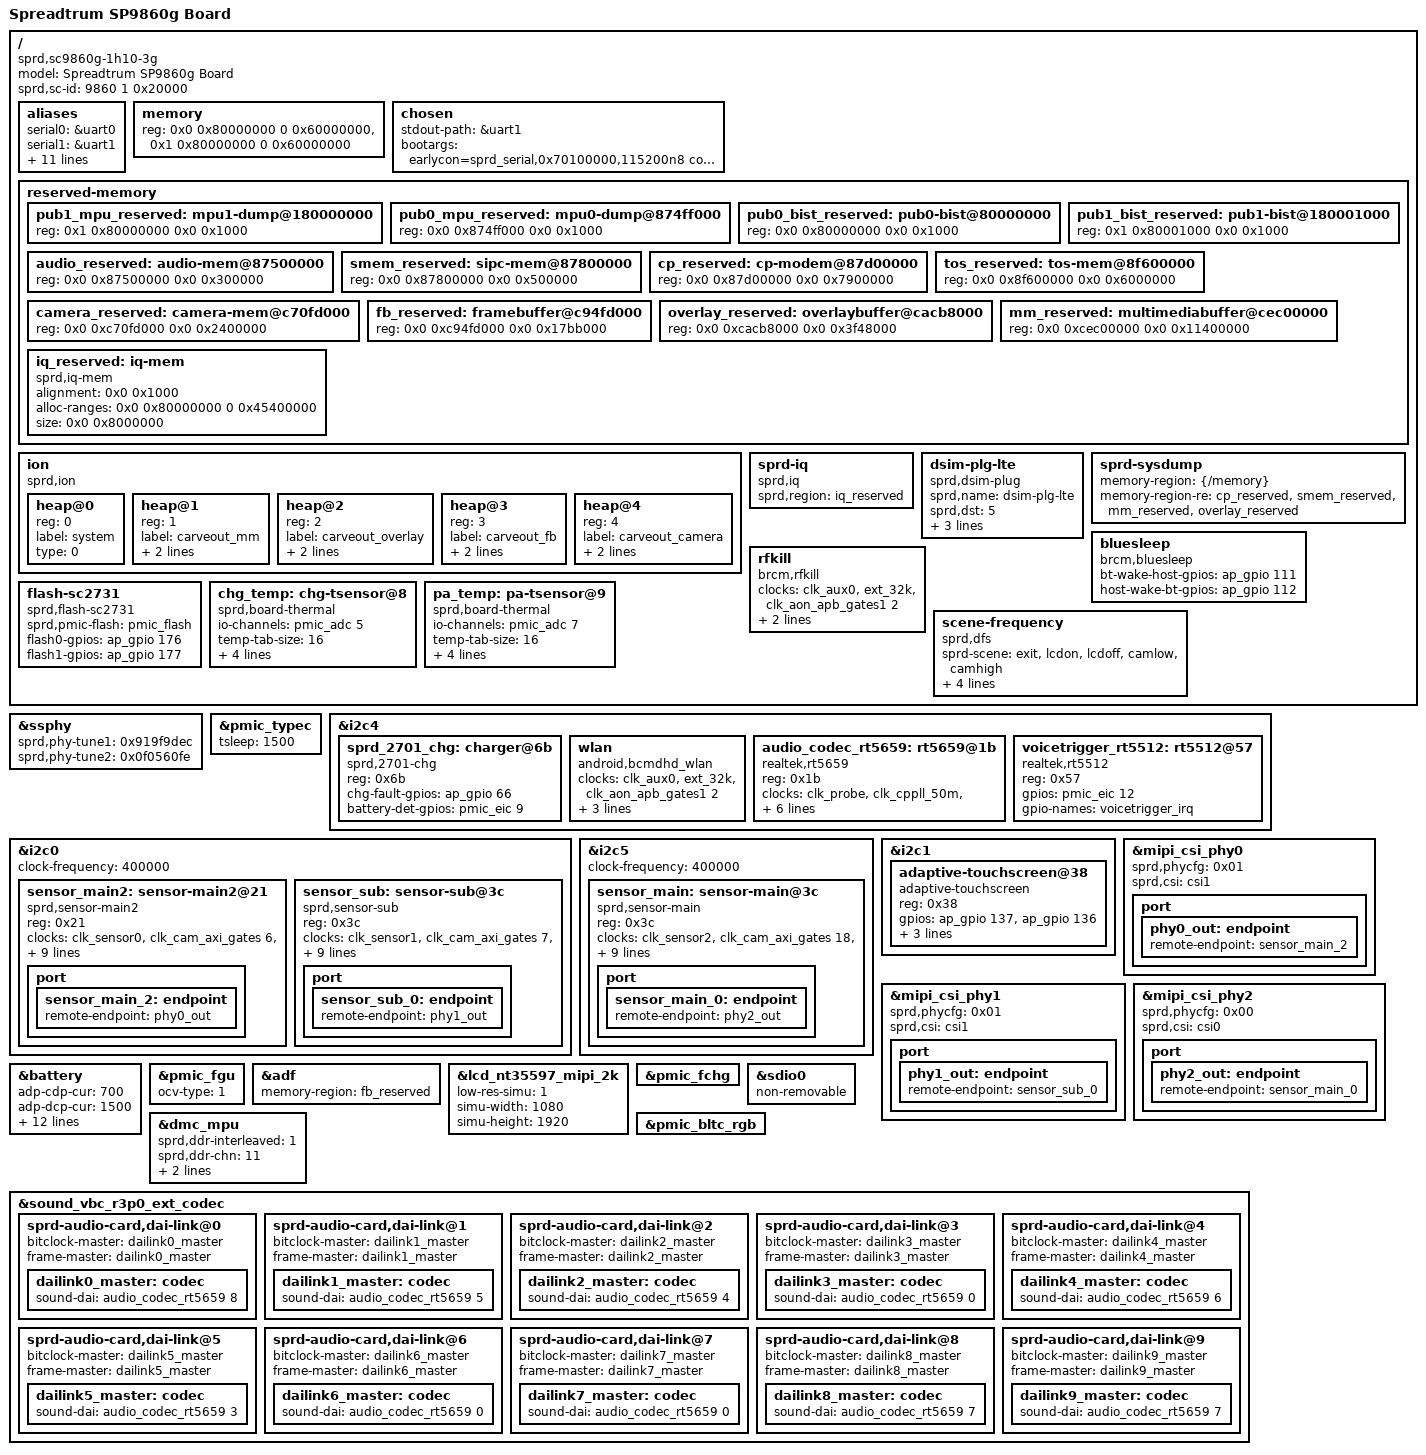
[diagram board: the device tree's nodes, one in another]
/*
 * Spreadtrum SP9860g board DTS file
 *
 * Copyright (C) 2016, Spreadtrum Communications Inc.
 *
 * This file is licensed under a dual GPLv2 or X11 license.
 */

/dts-v1/;

#include "sc9860g.dtsi"
#include "sc2731.dtsi"
#include "sprd-battery.dtsi"
#include "sp98x0-common.dtsi"
#include "sprd-sound.dtsi"

/ {
	model = "Spreadtrum SP9860g Board";

	compatible = "sprd,sc9860g-1h10-3g";

	sprd,sc-id = <9860 1 0x20000>;

	aliases {
		serial0 = &uart0;
		serial1 = &uart1;
		serial2 = &uart2;
		serial3 = &uart3;
		i2c0 = &i2c0;
		i2c1 = &i2c1;
		i2c4 = &i2c4;
		i2c5 = &i2c5;
		hwspinlock1 = &hwslock1;
		dmc_mpu = &dmc_mpu;
		thm-sensor7 = &pmic_thermal;
		thm-sensor8 = &chg_temp;
		thm-sensor9 = &pa_temp;
	};

	memory{
		device_type = "memory";
		reg = <0x0 0x80000000 0 0x60000000>, <0x1 0x80000000 0 0x60000000>;
	};

	chosen {
		stdout-path = &uart1;
		bootargs = "earlycon=sprd_serial,0x70100000,115200n8 console=ttyS1,115200n8 loglevel=1 androidboot.hardware=sp9860g_1h10_3g memblock=debug bootmem_debug=1";
	};

	reserved-memory {
		#address-cells = <2>;
		#size-cells = <2>;
		ranges;

		pub1_mpu_reserved: mpu1-dump@180000000 {
			reg = <0x1 0x80000000 0x0 0x1000>;
		};

		pub0_mpu_reserved: mpu0-dump@874ff000 {
			reg = <0x0 0x874ff000 0x0 0x1000>;
		};

		pub0_bist_reserved: pub0-bist@80000000 {
			reg = <0x0 0x80000000 0x0 0x1000>;
		};

		pub1_bist_reserved: pub1-bist@180001000 {
			reg = <0x1 0x80001000 0x0 0x1000>;
		};

		audio_reserved: audio-mem@87500000 {
			reg = <0x0 0x87500000 0x0 0x300000>;
		};

		smem_reserved: sipc-mem@87800000 {
			reg = <0x0 0x87800000 0x0 0x500000>;
		};

		cp_reserved: cp-modem@87d00000 {
			reg = <0x0 0x87d00000 0x0 0x7900000>;
		};

		tos_reserved: tos-mem@8f600000 {
			reg = <0x0 0x8f600000 0x0 0x6000000>;
		};

		camera_reserved: camera-mem@c70fd000{
			reg = <0x0 0xc70fd000 0x0 0x2400000>;
		};

		fb_reserved: framebuffer@c94fd000{
			reg = <0x0 0xc94fd000 0x0 0x17bb000>;
		};

		overlay_reserved: overlaybuffer@cacb8000{
			reg = <0x0 0xcacb8000 0x0 0x3f48000>;
		};

		mm_reserved: multimediabuffer@cec00000{
			reg = <0x0 0xcec00000 0x0 0x11400000>;
		};

		iq_reserved: iq-mem{
			compatible = "sprd,iq-mem";
			alignment = <0x0 0x1000>;
			alloc-ranges = <0x0 0x80000000 0 0x45400000>;
			size = <0x0 0x8000000>;
		};
	};

	ion {
		compatible = "sprd,ion";
		#address-cells = <1>;
		#size-cells = <0>;

		heap@0 {
			reg = <0>;
			label = "system";
			type = <0>;
		};

		heap@1 {
			reg = <1>;
			label = "carveout_mm";
			type = <2>;
			memory-region = <&mm_reserved>;
		};

		heap@2 {
			reg = <2>;
			label = "carveout_overlay";
			type = <2>;
			memory-region = <&overlay_reserved>;
		};

		heap@3 {
			reg = <3>;
			label = "carveout_fb";
			type = <2>;
			memory-region = <&fb_reserved>;
		};

		heap@4 {
			reg = <4>;
			label = "carveout_camera";
			type = <2>;
			memory-region = <&camera_reserved>;
		};
	};

	sprd-iq {
		compatible = "sprd,iq";
		sprd,region = <&iq_reserved>;
	};

	dsim-plg-lte {
		compatible = "sprd,dsim-plug";
		sprd,name = "dsim-plg-lte";
		sprd,dst = <5>;
		sprd,channel = <23>;
		sim1-gpios = <&ap_gpio 40 0>;
		sim2-gpios = <&ap_gpio 41 0>;
	};

	sprd-sysdump {
		memory-region = <&{/memory}>;
		memory-region-re = <&cp_reserved>,<&smem_reserved>,
				<&mm_reserved>,<&overlay_reserved>;
	};

	bluesleep {
		compatible = "brcm,bluesleep";
		bt-wake-host-gpios = <&ap_gpio 111 0>;
		host-wake-bt-gpios = <&ap_gpio 112 0>;
	};

	rfkill {
		compatible = "brcm,rfkill";
		clock-names = "clk_32k","source","enable";
		clocks = <&clk_aux0>,<&ext_32k>,
			 <&clk_aon_apb_gates1 2>;
		power-gpios = <&ap_gpio 113 0>;
		reset-gpios = <&ap_gpio 122 0>;
	};

	flash-sc2731 {
		compatible = "sprd,flash-sc2731";
		sprd,pmic-flash = <&pmic_flash>;
		flash0-gpios = <&ap_gpio 176 0>;
		flash1-gpios = <&ap_gpio 177 0>;
	};

	chg_temp:chg-tsensor@8 {
		compatible = "sprd,board-thermal";
		#thermal-sensor-cells = <1>;
		io-channels = <&pmic_adc 5>;
		io-channel-names = "adc_temp";
		temp-tab-size = <16>;
		temp-tab-val = <1140 1132 1109 1074 983 838 654 413
				316 238 178 133 99 75 57 43>;
		temp-tab-temp = <558 596 704 806 953 1101 1248 1450
				1549 1649 1749 1849 1951 2049 2148 2252>;
	};

	pa_temp:pa-tsensor@9 {
		compatible = "sprd,board-thermal";
		#thermal-sensor-cells = <1>;
		io-channels = <&pmic_adc 7>;
		io-channel-names = "adc_temp";
		temp-tab-size = <16>;
		temp-tab-val = <1140 1132 1109 1074 983 838 654 413
				316 238 178 133 99 75 57 43>;
		temp-tab-temp = <558 596 704 806 953 1101 1248 1450
				1549 1649 1749 1849 1951 2049 2148 2252>;
	};

	scene-frequency {
		compatible = "sprd,dfs";
		sprd-scene = "exit", "lcdon", "lcdoff", "camlow", "camhigh";
		sprd-freq = <400 400 400 600 1200>;
		overflow = <4915200 12160000 17040000 98304000>;
		underflow = <0 3276800 11200000 16800000>;
		timer = <10>;
	};
};

&ssphy {
	sprd,phy-tune1 = <0x919f9dec>;
	sprd,phy-tune2 = <0x0f0560fe>;
};

&pmic_typec {
	tsleep = <1500>;
};

&i2c4 {
	status = "okay";
	sprd_2701_chg: charger@6b {
		compatible = "sprd,2701-chg";
		reg = <0x6b>;
		chg-fault-gpios = <&ap_gpio 66 0>;
		battery-det-gpios = <&pmic_eic 9 0>;
	};

	wlan {
		compatible = "android,bcmdhd_wlan";
		clock-names = "clk_32k","source","enable";
		clocks = <&clk_aux0>,<&ext_32k>,
			 <&clk_aon_apb_gates1 2>;
		wl-reg-on-gpios = <&ap_gpio 83 0>;
		wl-host-wake-gpios = <&ap_gpio 84 0>;
		sdhci-name = <&sdio1>;
	};

	audio_codec_rt5659: rt5659@1b {
		compatible = "realtek,rt5659";
		#sound-dai-cells = <1>;
		reg = <0x1b>;
		clock-names = "mclk", "source", "enable";
		clocks = <&clk_probe>, <&clk_cppll_50m>,
			 <&clk_aon_apb_gates1 5>;
		ldo-gpios = <&ap_gpio 181 0>;
		reset-gpios = <&ap_gpio 34 0>;
		realtek,gpio-jd2-sel = <7>; /* 0 ~ 7 <-> GPIO9 ~ GPIO15 */
		/* 0: uses 2 pins to detect hp; 1: uses 1 pin. */
		realtek,hp-det-one-pin = <1>;
		realtek,fixed-rate = <48000>; /* fixed sample rate. unit: Hz */
	};

	voicetrigger_rt5512: rt5512@57 {
		compatible = "realtek,rt5512";
		reg = <0x57>;
		gpios = <&pmic_eic 12 0> ;
		gpio-names = "voicetrigger_irq";
	};
};

&i2c0 {
	status = "okay";
	clock-frequency = <400000>;

	sensor_main2: sensor-main2@21 {
		compatible = "sprd,sensor-main2";
		reg = <0x21>;
		clock-names = "clk_src","sensor_eb",
			"clk_96m","clk_76m8",
			"clk_48m","clk_26m";
		clocks  = <&clk_sensor0>,<&clk_cam_axi_gates 6>,
			<&clk_twpll_96m>,<&clk_twpll_76m8>,
			<&clk_twpll_48m>,<&ext_26m>;
		vddio-supply = <&vddcamio>;
		vddcamd-supply = <&vddcamd1>;
		vddcama-supply = <&vddcama1>;
		vddcammot-supply = <&vddcammot>;
		reset-gpios = <&ap_gpio 123 0>;
		power-down-gpios = <&ap_gpio 124 0>;
		host = "dcam1";
		port {
			sensor_main_2: endpoint {
				remote-endpoint = <&phy0_out>;
			};
		};
	};

	sensor_sub: sensor-sub@3c {
		compatible = "sprd,sensor-sub";
		reg = <0x3c>;
		clock-names = "clk_src","sensor_eb",
			"clk_96m","clk_76m8",
			"clk_48m","clk_26m";
		clocks = <&clk_sensor1>,<&clk_cam_axi_gates 7>,
			<&clk_twpll_96m>,<&clk_twpll_76m8>,
			<&clk_twpll_48m>,<&ext_26m>;
		vddio-supply = <&vddcamio>;
		vddcama-supply = <&vddcama1>;
		vddcamd-supply = <&vddcamd1>;
		vddcammot-supply = <&vddcammot>;
		reset-gpios = <&ap_gpio 157 0>;
		power-down-gpios = <&ap_gpio 125 0>;
		host = "dcam1";
		port {
			sensor_sub_0: endpoint {
				remote-endpoint = <&phy1_out>;
			};
		};
	};

};

&i2c5 {
	status = "okay";
	clock-frequency = <400000>;

	sensor_main: sensor-main@3c {
		compatible = "sprd,sensor-main";
		reg = <0x3c>;
		clock-names = "clk_src","sensor_eb",
			"clk_96m","clk_76m8",
			"clk_48m","clk_26m";
		clocks = <&clk_sensor2>,<&clk_cam_axi_gates 18>,
			<&clk_twpll_96m>,<&clk_twpll_76m8>,
			<&clk_twpll_48m>,<&ext_26m>;
		vddio-supply = <&vddcamio>;
		vddcama-supply = <&vddcama0>;
		vddcamd-supply = <&vddcamd0>;
		vddcammot-supply = <&vddcammot>;
		reset-gpios = <&ap_gpio 168 0>;
		power-down-gpios = <&ap_gpio 169 0>;
		host = "dcam0";
		port {
			sensor_main_0: endpoint {
				remote-endpoint = <&phy2_out>;
			};
		};
	};

};

&i2c1 {
	status = "okay";

	adaptive-touchscreen@38 {
		compatible = "adaptive-touchscreen";
		reg = <0x38>;
		gpios = <&ap_gpio 137 0
			&ap_gpio 136 0>;
		controller = "focaltech,FT5x46";
		surface-width = <1080>;
		surface-height = <1920>;
	};
};

&mipi_csi_phy0 {
	status = "okay";

	sprd,phycfg = <0x01>;
	sprd,csi = <&csi1>;
	port {
		phy0_out: endpoint {
			remote-endpoint = <&sensor_main_2>;
		};
	};
};

&mipi_csi_phy1 {
	status = "okay";

	sprd,phycfg = <0x01>;
	sprd,csi = <&csi1>;
	port {
		phy1_out: endpoint {
			remote-endpoint = <&sensor_sub_0>;
		};
	};
};

&mipi_csi_phy2 {
	status = "okay";

	sprd,phycfg = <0x00>;
	sprd,csi = <&csi0>;
	port {
		phy2_out: endpoint {
			remote-endpoint = <&sensor_main_0>;
		};
	};
};

&battery {
	adp-cdp-cur = <700>;
	adp-dcp-cur = <1500>;
	adp-sdp-cur = <450>;
	chg-end-vol = <4350>;
	chg-end-vol-check = <4330>;
	chg-bat-safety-vol = <4430>;
	rechg-vol = <4270>;
	rsense-real = <100>;
	rint = <320>;
	cnom = <2780>;
	ocv-tab-vol = <4360 4249 4189 4133 4081 4034 3991
			3953 3910 3866 3836 3813 3795 3782
			3774 3765 3750 3726 3687 3658 3400>;
	ocv-tab-cap = <100  95   90   85   80   75   70
			65   60   55   50   45   40   35
			30   25   20   15   10   5    0>;
};

&pmic_fgu {
	ocv-type = <1>;
};

&adf {
	memory-region = <&fb_reserved>;
};

&lcd_nt35597_mipi_2k {
	low-res-simu = <1>;
	simu-width = <1080>;
	simu-height = <1920>;
};

&pmic_fchg {
	status = "okay";
};

&sdio0 {
	non-removable;
};

&dmc_mpu {
	sprd,ddr-interleaved = <1>;
	sprd,ddr-chn = <11>;
	memory-region = <&pub0_mpu_reserved>,<&pub1_mpu_reserved>;
};

&pmic_bltc_rgb {
	status = "okay";
};

&sound_vbc_r3p0_ext_codec {
	status = "okay";
	sprd-audio-card,dai-link@0 {
		bitclock-master = <&dailink0_master>;
		frame-master = <&dailink0_master>;
		dailink0_master: codec {
			/* rt5659-aif1 */
			sound-dai = <&audio_codec_rt5659 8>;
		};
	};
	sprd-audio-card,dai-link@1 {
		bitclock-master = <&dailink1_master>;
		frame-master = <&dailink1_master>;
		dailink1_master: codec {
			/* rt5659-aif1-voice */
			sound-dai = <&audio_codec_rt5659 5>;
		};
	};
	sprd-audio-card,dai-link@2 {
		bitclock-master = <&dailink2_master>;
		frame-master = <&dailink2_master>;
		dailink2_master: codec {
			/* rt5659-aif1-fast */
			sound-dai = <&audio_codec_rt5659 4>;
		};
	};
	sprd-audio-card,dai-link@3 {
		bitclock-master = <&dailink3_master>;
		frame-master = <&dailink3_master>;
		dailink3_master: codec {
			/* rt5659-aif1 */
			sound-dai = <&audio_codec_rt5659 0>;
		};
	};
	sprd-audio-card,dai-link@4 {
		bitclock-master = <&dailink4_master>;
		frame-master = <&dailink4_master>;
		dailink4_master: codec {
			/* rt5659-aif1-fm */
			sound-dai = <&audio_codec_rt5659 6>;
		};
	};
	sprd-audio-card,dai-link@5 {
		bitclock-master = <&dailink5_master>;
		frame-master = <&dailink5_master>;
		dailink5_master: codec {
			/* rt5659-aif1-ofld */
			sound-dai = <&audio_codec_rt5659 3>;
		};
	};
	sprd-audio-card,dai-link@6 {
		bitclock-master = <&dailink6_master>;
		frame-master = <&dailink6_master>;
		dailink6_master: codec {
			/* rt5659-aif1 */
			sound-dai = <&audio_codec_rt5659 0>;
		};
	};
	sprd-audio-card,dai-link@7 {
		bitclock-master = <&dailink7_master>;
		frame-master = <&dailink7_master>;
		dailink7_master: codec {
			/* rt5659-aif1 */
			sound-dai = <&audio_codec_rt5659 0>;
		};
	};
	sprd-audio-card,dai-link@8 {
		bitclock-master = <&dailink8_master>;
		frame-master = <&dailink8_master>;
		dailink8_master: codec {
			/* rt5659-aif1 */
			sound-dai = <&audio_codec_rt5659 7>;
		};
	};
	sprd-audio-card,dai-link@9 {
		bitclock-master = <&dailink9_master>;
		frame-master = <&dailink9_master>;
		dailink9_master: codec {
			/* rt5659-aif1 */
			sound-dai = <&audio_codec_rt5659 7>;
		};
	};
};

